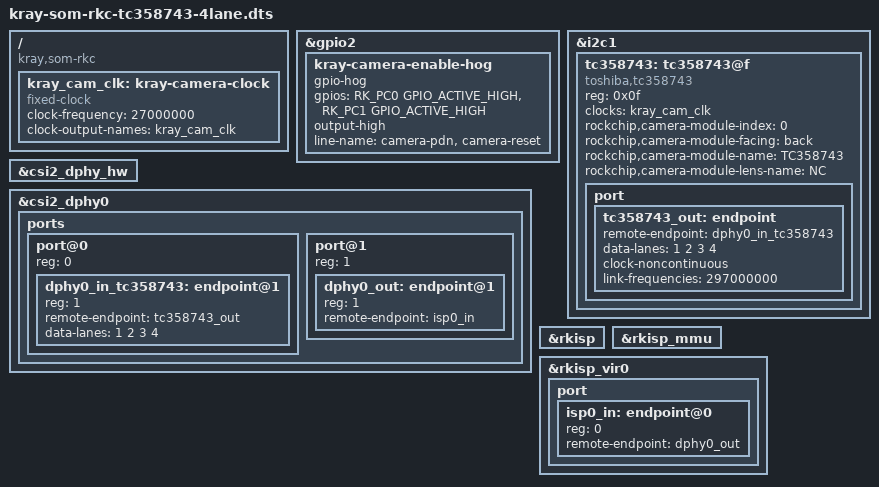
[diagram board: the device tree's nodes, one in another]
// SPDX-License-Identifier: (GPL-2.0+ OR MIT)
/*
 * Kray-SoM-RKC: HDMI input: Toshiba TC358743 HDMI-to-CSI-2 bridge
 * with a 4-lane (22-pin) CSI cable, e.g. the Geekworm C779,
 * on the CSI connector. Vendor kernel only.
 *
 *   /boot/armbianEnv.txt:  overlays=kray-som-rkc-tc358743-4lane
 *
 * Rockchip's tc35874x driver (built into the vendor kernel). Bridge on I2C1
 * at 0x0f, 27 MHz oscillator on the board, four MIPI CSI-2 lanes at 297 MHz
 * (594 Mbit/s per lane, the driver's reference setting) through csi2_dphy0
 * into rkisp (rkisp_vir0), UYVY, up to 1080p60 with the driver's own EDID.
 * No interrupt line: the driver polls for the HDMI signal. Camera power-down
 * (GPIO2_C0) and reset (GPIO2_C1) are held high.
 */

/dts-v1/;
/plugin/;

#include <dt-bindings/gpio/gpio.h>
#include <dt-bindings/pinctrl/rockchip.h>

/ {
	compatible = "kray,som-rkc", "rockchip,rk3566";

	fragment@0 {
		target-path = "/";
		__overlay__ {
			kray_cam_clk: kray-camera-clock {
				compatible = "fixed-clock";
				#clock-cells = <0>;
				clock-frequency = <27000000>;
				clock-output-names = "kray_cam_clk";
			};
		};
	};

	fragment@1 {
		target = <&gpio2>;
		__overlay__ {
			kray-camera-enable-hog {
				gpio-hog;
				/* GPIO2_C0: power-down (PDN), GPIO2_C1: reset */
				gpios = <RK_PC0 GPIO_ACTIVE_HIGH>, <RK_PC1 GPIO_ACTIVE_HIGH>;
				output-high;
				line-name = "camera-pdn", "camera-reset";
			};
		};
	};

	fragment@2 {
		target = <&i2c1>;
		__overlay__ {
			status = "okay";
			#address-cells = <1>;
			#size-cells = <0>;

			tc358743: tc358743@f {
				compatible = "toshiba,tc358743";
				reg = <0x0f>;
				clocks = <&kray_cam_clk>;
				clock-names = "refclk";
				rockchip,camera-module-index = <0>;
				rockchip,camera-module-facing = "back";
				rockchip,camera-module-name = "TC358743";
				rockchip,camera-module-lens-name = "NC";

				port {
					tc358743_out: endpoint {
						remote-endpoint = <&dphy0_in_tc358743>;
						data-lanes = <1 2 3 4>;
						clock-noncontinuous;
						link-frequencies = /bits/ 64 <297000000>;
					};
				};
			};
		};
	};

	fragment@3 {
		target = <&csi2_dphy_hw>;
		__overlay__ {
			status = "okay";
		};
	};

	fragment@4 {
		target = <&csi2_dphy0>;
		__overlay__ {
			status = "okay";

			ports {
				#address-cells = <1>;
				#size-cells = <0>;

				port@0 {
					reg = <0>;
					#address-cells = <1>;
					#size-cells = <0>;

					dphy0_in_tc358743: endpoint@1 {
						reg = <1>;
						remote-endpoint = <&tc358743_out>;
						data-lanes = <1 2 3 4>;
					};
				};

				port@1 {
					reg = <1>;
					#address-cells = <1>;
					#size-cells = <0>;

					dphy0_out: endpoint@1 {
						reg = <1>;
						remote-endpoint = <&isp0_in>;
					};
				};
			};
		};
	};

	fragment@5 {
		target = <&rkisp>;
		__overlay__ {
			status = "okay";
		};
	};

	fragment@6 {
		target = <&rkisp_mmu>;
		__overlay__ {
			status = "okay";
		};
	};

	fragment@7 {
		target = <&rkisp_vir0>;
		__overlay__ {
			status = "okay";

			port {
				#address-cells = <1>;
				#size-cells = <0>;

				isp0_in: endpoint@0 {
					reg = <0>;
					remote-endpoint = <&dphy0_out>;
				};
			};
		};
	};
};
